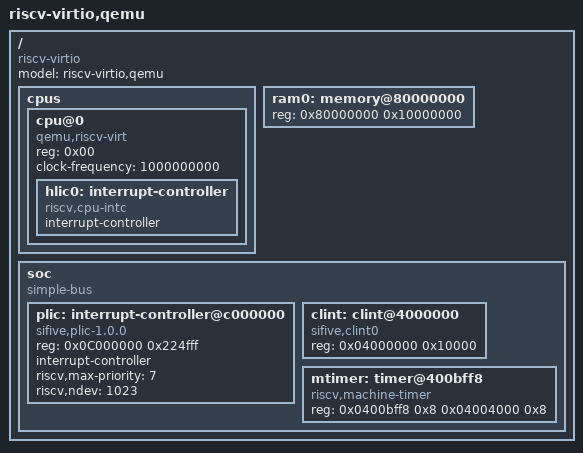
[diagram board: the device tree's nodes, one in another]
/*
 * Copyright (c) 2020 Cobham Gaisler AB
 * SPDX-License-Identifier: Apache-2.0
 */

#ifndef NRCPU
#define NRCPU 1
#endif

/dts-v1/;

/ {
	#address-cells = <0x01>;
	#size-cells = <0x01>;
	compatible = "riscv-virtio";
	model = "riscv-virtio,qemu";

	cpus {
		#address-cells = <0x01>;
		#size-cells = <0x00>;

		/* CPU 0 ist immer aktiv */
		cpu@0 {
			device_type = "cpu";
			reg = <0x00>;
			status = "okay";
			compatible = "qemu,riscv-virt", "riscv";
			clock-frequency = <1000000000>;

			hlic0: interrupt-controller {
				compatible = "riscv,cpu-intc";
				#address-cells = <0>;
				#interrupt-cells = <0x01>;
				interrupt-controller;
			};
		};

#if NRCPU > 1
		cpu@1 {
			device_type = "cpu";
			reg = <0x01>;
			status = "okay";
			compatible = "qemu,riscv-virt", "riscv";

			hlic1: interrupt-controller {
				compatible = "riscv,cpu-intc";
				#address-cells = <0>;
				#interrupt-cells = <0x01>;
				interrupt-controller;
			};
		};
#endif

#if NRCPU > 2
		cpu@2 {
			device_type = "cpu"; reg = <0x02>; status = "okay"; compatible = "qemu,riscv-virt", "riscv";
			hlic2: interrupt-controller { compatible = "riscv,cpu-intc"; #address-cells = <0>; #interrupt-cells = <0x01>; interrupt-controller; };
		};
		cpu@3 {
			device_type = "cpu"; reg = <0x03>; status = "okay"; compatible = "qemu,riscv-virt", "riscv";
			hlic3: interrupt-controller { compatible = "riscv,cpu-intc"; #address-cells = <0>; #interrupt-cells = <0x01>; interrupt-controller; };
		};
#endif

#if NRCPU > 4
		cpu@4 {
			device_type = "cpu"; reg = <0x04>; status = "okay"; compatible = "qemu,riscv-virt", "riscv";
			hlic4: interrupt-controller { compatible = "riscv,cpu-intc"; #address-cells = <0>; #interrupt-cells = <0x01>; interrupt-controller; };
		};
		cpu@5 {
			device_type = "cpu"; reg = <0x05>; status = "okay"; compatible = "qemu,riscv-virt", "riscv";
			hlic5: interrupt-controller { compatible = "riscv,cpu-intc"; #address-cells = <0>; #interrupt-cells = <0x01>; interrupt-controller; };
		};
		cpu@6 {
			device_type = "cpu"; reg = <0x06>; status = "okay"; compatible = "qemu,riscv-virt", "riscv";
			hlic6: interrupt-controller { compatible = "riscv,cpu-intc"; #address-cells = <0>; #interrupt-cells = <0x01>; interrupt-controller; };
		};
		cpu@7 {
			device_type = "cpu"; reg = <0x07>; status = "okay"; compatible = "qemu,riscv-virt", "riscv";
			hlic7: interrupt-controller { compatible = "riscv,cpu-intc"; #address-cells = <0>; #interrupt-cells = <0x01>; interrupt-controller; };
		};
#endif
	};

	ram0: memory@80000000 {
		device_type = "memory";
		reg = <0x80000000 0x10000000>;
	};

	soc {
		#address-cells = <0x01>;
		#size-cells = <0x01>;
		compatible = "simple-bus";
		ranges;


		plic: interrupt-controller@c000000 {
			compatible = "sifive,plic-1.0.0";
			reg = <0x0C000000 0x224fff>;
			interrupt-controller;
			riscv,max-priority = <7>;
			riscv,ndev = <1023>;
			#address-cells = <0x00>;
			#interrupt-cells = <0x02>;
		};

		clint: clint@4000000 {
			compatible = "sifive,clint0";
			reg = <0x04000000 0x10000>;
		};
		mtimer: timer@400bff8 {
			compatible = "riscv,machine-timer";
			reg = <0x0400bff8 0x8 0x04004000 0x8>;
			reg-names = "mtime", "mtimecmp";
		};
	};
};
